VERSION ""

NS_ :

BS_:

BU_: XXX

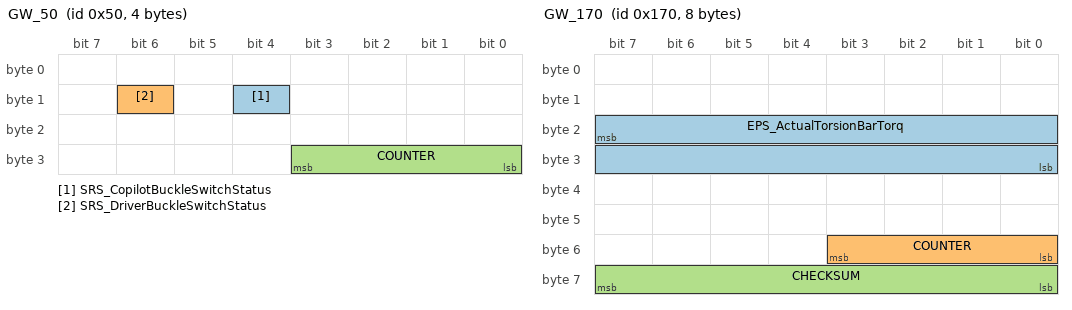
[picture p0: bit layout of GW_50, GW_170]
BO_ 80 GW_50: 4 XXX
 SG_ SRS_CopilotBuckleSwitchStatus : 12|1@0+ (1,0) [0|1] "" XXX
 SG_ SRS_DriverBuckleSwitchStatus : 14|1@0+ (1,0) [0|1] "" XXX
 SG_ COUNTER : 27|4@0+ (1,0) [0|15] "" XXX

BO_ 368 GW_170: 8 ESP
 SG_ EPS_ActualTorsionBarTorq : 23|16@0+ (1,-5533) [0|65535] "" XXX
 SG_ COUNTER : 51|4@0+ (1,0) [0|15] "" XXX
 SG_ CHECKSUM : 63|8@0+ (1,0) [0|255] "" XXX

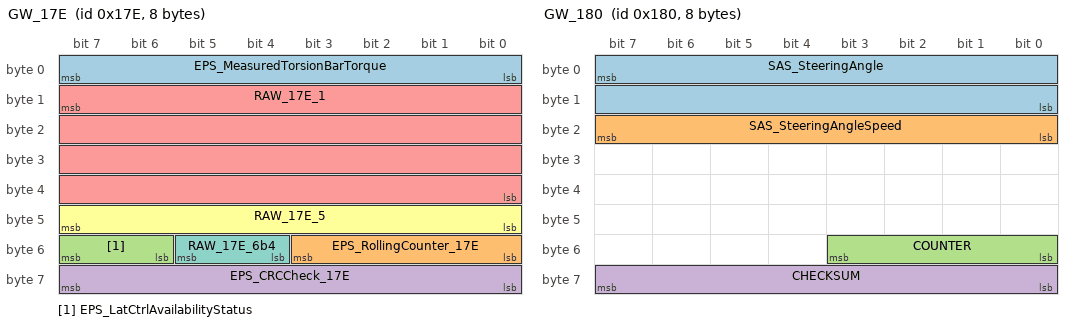
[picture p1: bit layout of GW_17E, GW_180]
BO_ 382 GW_17E: 8 XXX
 SG_ EPS_MeasuredTorsionBarTorque : 7|8@0+ (1,-126) [-126|129] "Nm" XXX
 SG_ EPS_RollingCounter_17E : 51|4@0+ (1,0) [0|15] "" XXX
 SG_ EPS_LatCtrlAvailabilityStatus : 55|2@0+ (1,0) [0|3] "" XXX
 SG_ EPS_CRCCheck_17E : 63|8@0+ (1,0) [0|255] "" XXX
 SG_ RAW_17E_1 : 15|32@0+ (1,0) [0|4294967295] "" XXX
 SG_ RAW_17E_5 : 47|8@0+ (1,0) [0|255] "" XXX
 SG_ RAW_17E_6b4 : 53|2@0+ (1,0) [0|3] "" XXX

BO_ 384 GW_180: 8 XXX
 SG_ SAS_SteeringAngle : 7|16@0- (0.015625,0) [-512|512] "deg" XXX
 SG_ SAS_SteeringAngleSpeed : 23|8@0+ (1,0) [0|255] "" XXX
 SG_ COUNTER : 51|4@0+ (1,0) [0|15] "" XXX
 SG_ CHECKSUM : 63|8@0+ (1,0) [0|255] "" XXX

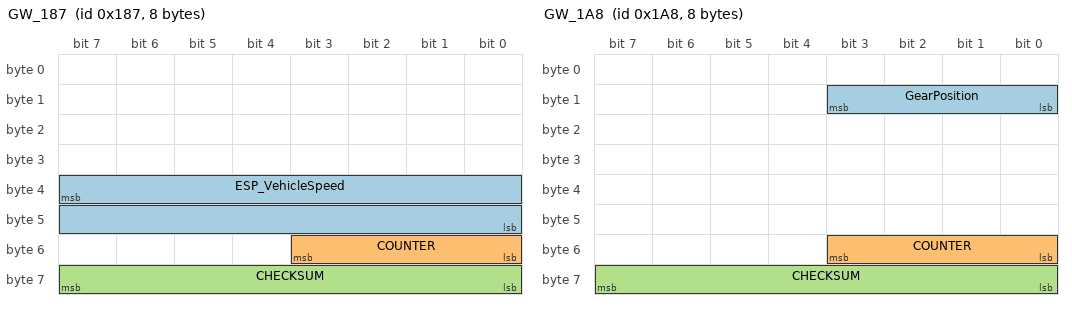
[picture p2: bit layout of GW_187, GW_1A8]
BO_ 391 GW_187: 8 XXX
 SG_ ESP_VehicleSpeed : 39|16@0+ (0.06,0) [0|255] "km/h" XXX
 SG_ COUNTER : 51|4@0+ (1,0) [0|15] "" XXX
 SG_ CHECKSUM : 63|8@0+ (1,0) [0|255] "" XXX

BO_ 392 GW_188: 8 XXX
 SG_ ESP_StatusByte : 7|8@0+ (1,0) [0|255] "" XXX

BO_ 407 GW_197: 8 XXX
 SG_ ESP_EspActive : 2|1@0+ (1,0) [0|1] "" XXX
 SG_ ESP_EspDisabled : 7|1@0+ (1,0) [0|1] "" XXX

BO_ 424 GW_1A8: 8 XXX
 SG_ GearPosition : 8|4@1+ (1,0) [0|15] "" XXX
 SG_ COUNTER : 51|4@0+ (1,0) [0|15] "" XXX
 SG_ CHECKSUM : 63|8@0+ (1,0) [0|255] "" XXX

BO_ 442 GW_1BA: 32 XXX
 SG_ ACC_MotorTorqueMinLimitRequest : 7|8@0+ (1,0) [0|255] "" XXX
 SG_ ACC_MotorTorqueMaxLimitRequest : 15|8@0+ (1,0) [0|255] "" XXX
 SG_ EPS_AngleCmd : 23|24@0- (0.0009765625,-6000.5) [-512|512] "deg" XXX
 SG_ ACC_RollingCounter_1BA : 51|4@0+ (1,0) [0|15] "" XXX
 SG_ ACC_CRCCheck_1BA : 63|8@0+ (1,0) [0|255] "" XXX

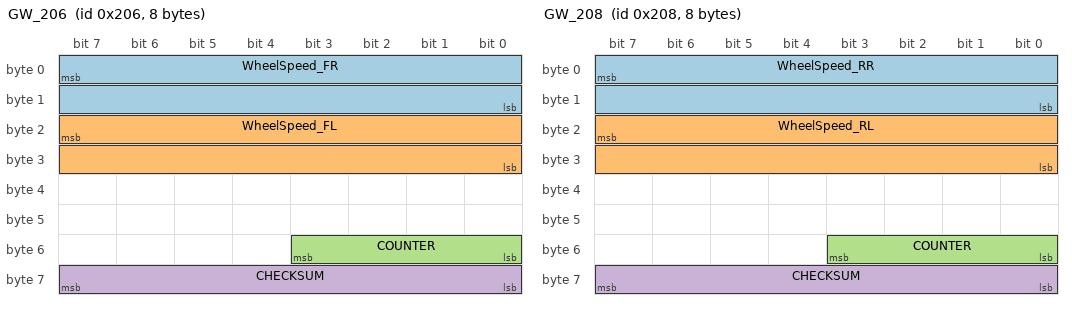
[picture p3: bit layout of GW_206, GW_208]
BO_ 518 GW_206: 8 XXX
 SG_ WheelSpeed_FR : 7|16@0+ (0.06,0) [0|255] "km/h" XXX
 SG_ WheelSpeed_FL : 23|16@0+ (0.06,0) [0|255] "km/h" XXX
 SG_ COUNTER : 51|4@0+ (1,0) [0|15] "" XXX
 SG_ CHECKSUM : 63|8@0+ (1,0) [0|255] "" XXX

BO_ 520 GW_208: 8 XXX
 SG_ WheelSpeed_RR : 7|16@0+ (0.06,0) [0|255] "km/h" XXX
 SG_ WheelSpeed_RL : 23|16@0+ (0.06,0) [0|255] "km/h" XXX
 SG_ COUNTER : 51|4@0+ (1,0) [0|15] "" XXX
 SG_ CHECKSUM : 63|8@0+ (1,0) [0|255] "" XXX

BO_ 580 GW_244: 32 XXX
 SG_ ACC_ACCTargetAcceleration : 7|16@0- (0.001,-25.6) [-10|10] "m/s2" XXX
 SG_ ACC_AEBCtrlType : 34|3@0+ (1,0) [0|7] "" XXX
 SG_ ACC_FCWPreWarning : 35|1@0+ (1,0) [0|1] "" XXX
 SG_ ACC_AccTrqReqActive : 44|1@0+ (1,0) [0|1] "" XXX
 SG_ ACC_RollingCounter_24E : 51|4@0+ (1,0) [0|15] "" XXX
 SG_ ACC_ACCMode : 54|3@0+ (1,0) [0|7] "" XXX
 SG_ ACC_ACCReq : 55|1@0+ (1,0) [0|1] "" XXX
 SG_ ACC_CRCCheck_24E : 63|8@0+ (1,0) [0|255] "" XXX
 SG_ ACC_AccTrqReq : 103|16@0+ (0.01,0) [0|45] "Nm" XXX
 SG_ ACC_RollingCounter_25E : 115|4@0+ (1,0) [0|15] "" XXX
 SG_ ACC_CRCCheck_25E : 127|8@0+ (1,0) [0|255] "" XXX
 SG_ RAW_244_2 : 23|16@0+ (1,0) [0|65535] "" XXX
 SG_ RAW_244_4b4 : 39|4@0+ (1,0) [0|15] "" XXX
 SG_ RAW_244_5b0 : 43|4@0+ (1,0) [0|15] "" XXX
 SG_ RAW_244_5b5 : 47|3@0+ (1,0) [0|7] "" XXX
 SG_ RAW_244_8 : 71|32@0+ (1,0) [0|4294967295] "" XXX
 SG_ RAW_244_14b4 : 119|4@0+ (1,0) [0|15] "" XXX
 SG_ RAW_244_16 : 135|32@0+ (1,0) [0|4294967295] "" XXX
 SG_ RAW_244_20 : 167|32@0+ (1,0) [0|4294967295] "" XXX
 SG_ RAW_244_24 : 199|32@0+ (1,0) [0|4294967295] "" XXX
 SG_ RAW_244_28 : 231|32@0+ (1,0) [0|4294967295] "" XXX

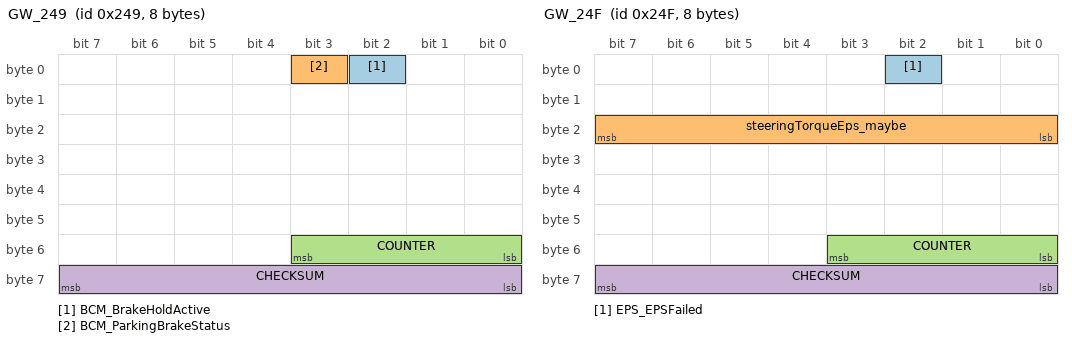
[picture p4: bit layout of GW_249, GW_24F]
BO_ 585 GW_249: 8 XXX
 SG_ BCM_BrakeHoldActive : 2|1@0+ (1,0) [0|1] "" XXX
 SG_ BCM_ParkingBrakeStatus : 3|1@0+ (1,0) [0|1] "" XXX
 SG_ COUNTER : 51|4@0+ (1,0) [0|15] "" XXX
 SG_ CHECKSUM : 63|8@0+ (1,0) [0|255] "" XXX

BO_ 591 GW_24F: 8 XXX
 SG_ EPS_EPSFailed : 2|1@0+ (1,0) [0|1] "" XXX
 SG_ steeringTorqueEps_maybe : 23|8@0- (0.1,0) [-12.8|12.7] "" XXX
 SG_ COUNTER : 51|4@0+ (1,0) [0|15] "" XXX
 SG_ CHECKSUM : 63|8@0+ (1,0) [0|255] "" XXX

BO_ 600 GW_258: 8 XXX
 SG_ GW258_Type M : 4|4@1+ (1,0) [0|15] "" XXX
 SG_ ESP_BrakePedalDepthHi m0 : 0|1@1+ (1,0) [0|1] "" XXX
 SG_ ESP_BrakePedalDepthLo m0 : 8|8@1+ (1,0) [0|255] "" XXX
 SG_ RAW_258_T1_1 m1 : 8|8@1+ (1,0) [0|255] "" XXX
 SG_ RAW_258_T1_2 m1 : 16|32@1+ (1,0) [0|4294967295] "" XXX
 SG_ RAW_258_T4_1 m4 : 8|8@1+ (1,0) [0|255] "" XXX
 SG_ RAW_258_T4_2 m4 : 16|32@1+ (1,0) [0|4294967295] "" XXX
 SG_ RAW_258_T5_1 m5 : 8|8@1+ (1,0) [0|255] "" XXX
 SG_ RAW_258_T5_2 m5 : 16|32@1+ (1,0) [0|4294967295] "" XXX
 SG_ COUNTER : 51|4@0+ (1,0) [0|15] "" XXX
 SG_ CHECKSUM : 63|8@0+ (1,0) [0|255] "" XXX

BO_ 618 GW_26A: 8 XXX
 SG_ EMS_AccelSwitch : 0|1@0+ (1,0) [0|1] "" XXX
 SG_ AcceleratorPedalPosition : 47|8@0+ (1,-31) [0|213] "%" XXX

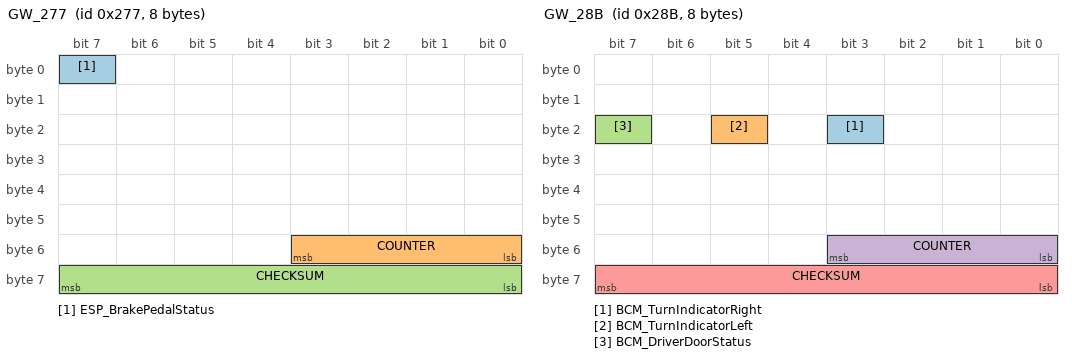
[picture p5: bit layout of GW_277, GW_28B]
BO_ 631 GW_277: 8 XXX
 SG_ ESP_BrakePedalStatus : 7|1@0+ (1,0) [0|1] "" XXX
 SG_ COUNTER : 51|4@0+ (1,0) [0|15] "" XXX
 SG_ CHECKSUM : 63|8@0+ (1,0) [0|255] "" XXX

BO_ 651 GW_28B: 8 XXX
 SG_ BCM_TurnIndicatorRight : 19|1@0+ (1,0) [0|1] "" XXX
 SG_ BCM_TurnIndicatorLeft : 21|1@0+ (1,0) [0|1] "" XXX
 SG_ BCM_DriverDoorStatus : 23|1@0+ (1,0) [0|1] "" XXX
 SG_ COUNTER : 51|4@0+ (1,0) [0|15] "" XXX
 SG_ CHECKSUM : 63|8@0+ (1,0) [0|255] "" XXX

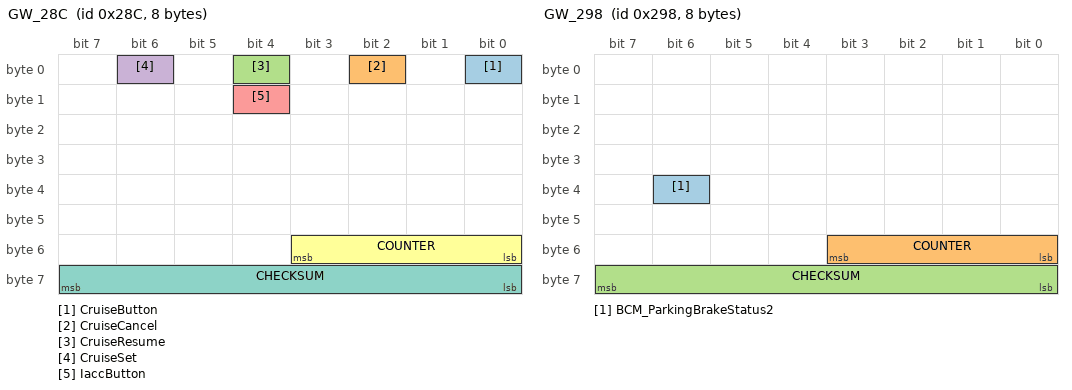
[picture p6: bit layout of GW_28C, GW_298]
BO_ 652 GW_28C: 8 XXX
 SG_ CruiseButton : 0|1@0+ (1,0) [0|1] "" XXX
 SG_ CruiseCancel : 2|1@0+ (1,0) [0|1] "" XXX
 SG_ CruiseResume : 4|1@0+ (1,0) [0|1] "" XXX
 SG_ CruiseSet : 6|1@0+ (1,0) [0|1] "" XXX
 SG_ IaccButton : 12|1@0+ (1,0) [0|1] "" XXX
 SG_ COUNTER : 51|4@0+ (1,0) [0|15] "" XXX
 SG_ CHECKSUM : 63|8@0+ (1,0) [0|255] "" XXX

BO_ 664 GW_298: 8 XXX
 SG_ BCM_ParkingBrakeStatus2 : 38|1@0+ (1,0) [0|1] "" XXX
 SG_ COUNTER : 51|4@0+ (1,0) [0|15] "" XXX
 SG_ CHECKSUM : 63|8@0+ (1,0) [0|255] "" XXX

BO_ 775 GW_307: 64 XXX
 SG_ ACC_SetSpeed : 7|16@0+ (0.0078125,0) [0|250] "km/h" XXX
 SG_ ACC_DistanceLevel : 17|2@0+ (1,0) [0|3] "" XXX
 SG_ ACC_RollingCounter_35E : 51|4@0+ (1,0) [0|15] "" XXX
 SG_ ACC_CRCCheck_35E : 63|8@0+ (1,0) [0|255] "" XXX
 SG_ ACC_RollingCounter_322 : 115|4@0+ (1,0) [0|15] "" XXX
 SG_ ACC_CRCCheck_322 : 127|8@0+ (1,0) [0|255] "" XXX
 SG_ ACC_RollingCounter_344 : 179|4@0+ (1,0) [0|15] "" XXX
 SG_ ACC_CRCCheck_344 : 191|8@0+ (1,0) [0|255] "" XXX
 SG_ ACC_RollingCounter_35F : 243|4@0+ (1,0) [0|15] "" XXX
 SG_ ACC_CRCCheck_35F : 255|8@0+ (1,0) [0|255] "" XXX
 SG_ RAW_307_2b2 : 23|6@0+ (1,0) [0|63] "" XXX
 SG_ RAW_307_3 : 31|24@0+ (1,0) [0|16777215] "" XXX
 SG_ RAW_307_6b4 : 55|4@0+ (1,0) [0|15] "" XXX
 SG_ RAW_307_8 : 71|32@0+ (1,0) [0|4294967295] "" XXX
 SG_ RAW_307_12 : 103|16@0+ (1,0) [0|65535] "" XXX
 SG_ RAW_307_14b4 : 119|4@0+ (1,0) [0|15] "" XXX
 SG_ RAW_307_16 : 135|32@0+ (1,0) [0|4294967295] "" XXX
 SG_ RAW_307_20 : 167|16@0+ (1,0) [0|65535] "" XXX
 SG_ RAW_307_22b4 : 183|4@0+ (1,0) [0|15] "" XXX
 SG_ RAW_307_24 : 199|32@0+ (1,0) [0|4294967295] "" XXX
 SG_ RAW_307_28 : 231|16@0+ (1,0) [0|65535] "" XXX
 SG_ RAW_307_30b4 : 247|4@0+ (1,0) [0|15] "" XXX
 SG_ RAW_307_32 : 263|32@0+ (1,0) [0|4294967295] "" XXX
 SG_ RAW_307_36 : 295|32@0+ (1,0) [0|4294967295] "" XXX
 SG_ RAW_307_40 : 327|32@0+ (1,0) [0|4294967295] "" XXX
 SG_ RAW_307_44 : 359|32@0+ (1,0) [0|4294967295] "" XXX
 SG_ RAW_307_48 : 391|32@0+ (1,0) [0|4294967295] "" XXX
 SG_ RAW_307_52 : 423|32@0+ (1,0) [0|4294967295] "" XXX
 SG_ RAW_307_56 : 455|32@0+ (1,0) [0|4294967295] "" XXX
 SG_ RAW_307_60 : 487|32@0+ (1,0) [0|4294967295] "" XXX

BO_ 794 GW_31A: 64 XXX
 SG_ GW31A_BSD_WarnLeft : 43|1@0+ (1,0) [0|1] "" XXX
 SG_ GW31A_BSD_WarnRight : 44|1@0+ (1,0) [0|1] "" XXX
 SG_ GW31A_BSD_WarnActive : 46|1@0+ (1,0) [0|1] "" XXX
 SG_ ACC_RollingCounter_36D : 51|4@0+ (1,0) [0|15] "" XXX
 SG_ ACC_CRCCheck_36D : 63|8@0+ (1,0) [0|255] "" XXX
 SG_ ACC_IACCHWAEnable : 68|1@0+ (1,0) [0|1] "" XXX
 SG_ ACC_TargetBasedLateralControl : 96|1@0+ (1,0) [0|1] "" XXX
 SG_ ACC_RollingCounter_30A : 115|4@0+ (1,0) [0|15] "" XXX
 SG_ ACC_CRCCheck_30A : 127|8@0+ (1,0) [0|255] "" XXX
 SG_ ACC_IACCHWAMode : 135|3@0+ (1,0) [0|7] "" XXX
 SG_ ACC_RollingCounter_30D : 179|4@0+ (1,0) [0|15] "" XXX
 SG_ ACC_CRCCheck_30D : 191|8@0+ (1,0) [0|255] "" XXX
 SG_ ACC_RollingCounter_367 : 243|4@0+ (1,0) [0|15] "" XXX
 SG_ ACC_CRCCheck_367 : 255|8@0+ (1,0) [0|255] "" XXX
 SG_ RAW_31A_0 : 7|32@0+ (1,0) [0|4294967295] "" XXX
 SG_ RAW_31A_4 : 39|8@0+ (1,0) [0|255] "" XXX
 SG_ RAW_31A_5b0 : 42|3@0+ (1,0) [0|7] "" XXX
 SG_ RAW_31A_5b5 : 45|1@0+ (1,0) [0|1] "" XXX
 SG_ RAW_31A_5b7 : 47|1@0+ (1,0) [0|1] "" XXX
 SG_ RAW_31A_6b4 : 55|4@0+ (1,0) [0|15] "" XXX
 SG_ RAW_31A_8b0 : 67|4@0+ (1,0) [0|15] "" XXX
 SG_ RAW_31A_8b5 : 71|3@0+ (1,0) [0|7] "" XXX
 SG_ RAW_31A_9 : 79|24@0+ (1,0) [0|16777215] "" XXX
 SG_ RAW_31A_12b1 : 103|7@0+ (1,0) [0|127] "" XXX
 SG_ RAW_31A_13 : 111|8@0+ (1,0) [0|255] "" XXX
 SG_ RAW_31A_14b4 : 119|4@0+ (1,0) [0|15] "" XXX
 SG_ RAW_31A_16b0 : 132|5@0+ (1,0) [0|31] "" XXX
 SG_ RAW_31A_17 : 143|32@0+ (1,0) [0|4294967295] "" XXX
 SG_ RAW_31A_21 : 175|8@0+ (1,0) [0|255] "" XXX
 SG_ RAW_31A_22b4 : 183|4@0+ (1,0) [0|15] "" XXX
 SG_ RAW_31A_24 : 199|32@0+ (1,0) [0|4294967295] "" XXX
 SG_ RAW_31A_28 : 231|16@0+ (1,0) [0|65535] "" XXX
 SG_ RAW_31A_30b4 : 247|4@0+ (1,0) [0|15] "" XXX
 SG_ RAW_31A_32 : 263|32@0+ (1,0) [0|4294967295] "" XXX
 SG_ RAW_31A_36 : 295|32@0+ (1,0) [0|4294967295] "" XXX
 SG_ RAW_31A_40 : 327|32@0+ (1,0) [0|4294967295] "" XXX
 SG_ RAW_31A_44 : 359|32@0+ (1,0) [0|4294967295] "" XXX
 SG_ RAW_31A_48 : 391|32@0+ (1,0) [0|4294967295] "" XXX
 SG_ RAW_31A_52 : 423|32@0+ (1,0) [0|4294967295] "" XXX
 SG_ RAW_31A_56 : 455|32@0+ (1,0) [0|4294967295] "" XXX
 SG_ RAW_31A_60 : 487|32@0+ (1,0) [0|4294967295] "" XXX

CM_ BO_ 368 "EPS shiji niuju (EPS actual torsion bar torque GW_170, byte2-3, dai yanzheng)";
CM_ SG_ 368 EPS_ActualTorsionBarTorq "EPS shiji niuju (actual torsion bar torque, 23|16@0+ (1,-5533), dai yanzheng: 01.csv zhong byte2-3 bu lianxu, byte3 zhiyou 22 distinct zhi, kending yichang)";
CM_ BO_ 382 "EPS celiang niuju (EPS measured torsion bar torque GW_17E, byte0)";
CM_ SG_ 382 EPS_MeasuredTorsionBarTorque "jiashiyuan niuju (driver torque Nm, byte0 wufuhao + offset -126, 01.csv yanzheng: zhixing fenbu 0x7E=126 fengzhi, fanwei 81~220 -> -45~+94 Nm, jiu dingyi 7|12@0- cuowu)";
CM_ SG_ 382 EPS_LatCtrlAvailabilityStatus "CESHI hengxiang kongzhi keji zhuangtai (EPS lat ctrl availability, byte6 bits7,6, 01.csv zhiqu {0,1}, 0=83% 1=17%)";
CM_ BO_ 384 "zhuanxiangjiao (steering angle, 0|16@0- yanzheng)";
CM_ SG_ 384 SAS_SteeringAngle "zhuanxiangjiao du (steering angle deg)";
CM_ SG_ 384 SAS_SteeringAngleSpeed "zhuanxiangjiao sudu (steering angle rate)";
CM_ BO_ 391 "chesu xinhao (vehicle speed, GW_187)";
CM_ SG_ 391 ESP_VehicleSpeed "chesu km/h (vehicle speed)";
CM_ BO_ 392 "ESP xinxi (ESP info GW_188, byte0 zhuangtai, dai shiche yanzheng)";
CM_ SG_ 392 ESP_StatusByte "ESP zhuangtai zhi (ESP status raw byte0, dai yanzheng: 01.csv zhi {0x00,0x01,0x20,0x60}, yubei espActive/espDisabled rongyu)";
CM_ BO_ 407 "ESP zhuangtai (ESP state GW_197, zhong zhiyindu, dai shiche yanzheng)";
CM_ SG_ 407 ESP_EspActive "ESP ganyu (ESP active intervention, byte0 bit2, 0x01->0x05 fanzhuan)";
CM_ SG_ 407 ESP_EspDisabled "ESP guanbi (ESP disabled, byte0 bit7, 01.csv qidong t=0s shi byte0=0xC0, zhihou zhuan 0x01)";
CM_ BO_ 424 "dangwei (gear, 0x1A8 byte1 low nibble: 0x00=N, 0x01-0x07=1-7, 0x09=R, 0x0A=P)";
CM_ SG_ 424 GearPosition "dangwei";
CM_ BO_ 442 "ADAS kongzhi mingling (ACC control command GW_1BA, 32 bytes)";
CM_ SG_ 442 EPS_AngleCmd "jiaodu mingling (EPS angle command: raw24 = 0x5DC200 + deg*1024, i.e. 1/1024 deg/LSB with offset -6000.5; equals GW_180 SAS_SteeringAngle_raw * 16)";
CM_ SG_ 518 WheelSpeed_FR "Special raw value 0x4000 = standstill (while 0x187 speed=0x0000); do not decode as vehicle speed.";
CM_ SG_ 518 WheelSpeed_FL "Special raw value 0x4000 = standstill (while 0x187 speed=0x0000); do not decode as vehicle speed.";
CM_ SG_ 520 WheelSpeed_RR "Special raw value 0x4000 = standstill (while 0x187 speed=0x0000); do not decode as vehicle speed.";
CM_ SG_ 520 WheelSpeed_RL "Special raw value 0x4000 = standstill (while 0x187 speed=0x0000); do not decode as vehicle speed.";
CM_ BO_ 580 "ACC zhuangtai (ACC status GW_244, 32 bytes)";
CM_ SG_ 580 ACC_ACCTargetAcceleration "ACC mubiao jiasudu (ACC target acceleration m/s2, raw*0.001-25.6)";
CM_ SG_ 580 ACC_AEBCtrlType "AEB kongzhi leixing (AEB control type, 0=none)";
CM_ SG_ 580 ACC_FCWPreWarning "QZDY yujing (FCW pre-warning, 0=no 1=yes)";
CM_ SG_ 580 ACC_ACCMode "ACC moshi (ACC mode 54|3@0+, 2=standby 3=active 7=fault)";
CM_ SG_ 580 ACC_ACCReq "ACC qingqiu (ACC request, byte6 bit7)";
CM_ SG_ 580 ACC_AccTrqReq "ACC niuju qingqiu (ACC torque request, non-zero=active; 01.csv xiuzheng: raw wei 4 de beishu, fanwei 108~4308, scale=0.01 -> [1.08,43.08] Nm)";
CM_ BO_ 585 "BCM zhuangtai (BCM state GW_249, zhong zhiyindu, dai shiche yanzheng)";
CM_ SG_ 585 BCM_BrakeHoldActive "zidong zhuche (auto hold, byte0 bit2, oufa 0x04)";
CM_ SG_ 585 BCM_ParkingBrakeStatus "zhuchedong (parking brake, byte0 bit3, 01.csv t=199s hou wei 0x08)";
CM_ BO_ 591 "EPS guzhuang (EPS fault GW_24F, 8 bytes)";
CM_ SG_ 591 EPS_EPSFailed "EPS guzhuang (EPS failed, byte0 bit2, WUDINGYI: byte0 shi fuzhi xinhao jingzhi=1 kuaizhuan=43, zhengchang kuaiman zhuanxiang shi wuchufa 2%)";
CM_ SG_ 591 steeringTorqueEps_maybe "EPS niuju yubei (EPS torque maybe, byte2 youfuhao 0.1, 01.csv 127 wei zhongxin, yu 0x17E byte0 danziangliang)";
CM_ BO_ 600 "shache taban shendu (brake pedal depth GW_258, muxed subframes; 01.csv quancheng Type={0,1,4,5}, Type0=12373zhen shendu[0,485] 500=100%, Type1/4/5 wei qita zizhen; COUNTER/CHECKSUM za sanyouzhen jun cunzai, gonggong)";
CM_ SG_ 600 GW258_Type "zizhen leixing (subframe type, byte0 high nibble: 0=PedalFrame, 1/4/5=other subframes, 01.csv Type 0/1/4/5)";
CM_ SG_ 600 ESP_BrakePedalDepthHi "shache taban shendu di 9 wei (brake pedal depth bit8, value=Lo|Hi<<8, 500=100%)";
CM_ SG_ 600 ESP_BrakePedalDepthLo "shache taban shendu di 8 wei (brake pedal depth low byte)";
CM_ BO_ 618 "youmen taban (accel pedal GW_26A)";
CM_ SG_ 618 EMS_AccelSwitch "youmen kaiguan byte0 bit0 (accel switch, 0=release 1=pressed)";
CM_ SG_ 618 AcceleratorPedalPosition "youmen kaidu % (accel pedal position, byte5 raw: 31=0%, 136=floor by accanjian.csv)";
CM_ BO_ 631 "shache taban (brake pedal GW_277)";
CM_ BO_ 651 "cheshen kongzhi BCM (body control: doors/turn signals)";
CM_ SG_ 651 BCM_TurnIndicatorRight "you zhuanxiang deng (right turn signal)";
CM_ SG_ 651 BCM_TurnIndicatorLeft "zuo zhuanxiang deng (left turn signal)";
CM_ BO_ 652 "fangxiangpan anjian (steering wheel buttons)";
CM_ SG_ 652 CruiseButton "dingsu";
CM_ SG_ 652 CruiseCancel "Exit_IACC";
CM_ SG_ 652 CruiseResume "RES+ anjian";
CM_ SG_ 652 CruiseSet "SET- anjian";
CM_ SG_ 652 IaccButton "IACC anjian";
CM_ BO_ 664 "BCM zhuangtai 2 (BCM state GW_298, rongyu, dai shiche yanzheng)";
CM_ SG_ 664 BCM_ParkingBrakeStatus2 "zhuchedong rongyu (parking brake redundant, byte4 bit6, 0x08->0x48 fanzhuan)";
CM_ BO_ 775 "ACC shezhi (ACC set speed/distance GW_307, 64 bytes, 4x16-byte sub-frames)";
CM_ SG_ 775 ACC_SetSpeed "ACC shezhi chesu (ACC set speed km/h, raw*0.0078125, verified 80.25/85.25/69.25)";
CM_ SG_ 775 ACC_DistanceLevel "ACC cheju dengji (ACC distance level, 0-3)";
CM_ BO_ 794 "IACC zhuangtai (IACC HWA status GW_31A, 64 bytes, 4x16-byte sub-frames)";
CM_ SG_ 794 GW31A_BSD_WarnLeft "chefanglaiche";
CM_ SG_ 794 GW31A_BSD_WarnRight "chefanglaiche";
CM_ SG_ 794 GW31A_BSD_WarnActive "chefanglaiche";
CM_ SG_ 794 ACC_IACCHWAEnable "IACC HWA keji (IACC HWA available, byte8 bit4, verified byte8=0x71->1)";
CM_ SG_ 794 ACC_TargetBasedLateralControl "HCEngji mubiao hengxiang kongzhi (HWA target-based lateral control, byte12 bit0)";
CM_ SG_ 794 ACC_IACCHWAMode "IACC HWA moshi (IACC HWA mode 135|3@0+, 7=fault)";
VAL_ 80 SRS_CopilotBuckleSwitchStatus 0 "close" 1 "open";
VAL_ 80 SRS_DriverBuckleSwitchStatus 0 "close" 1 "open";
VAL_ 382 EPS_LatCtrlAvailabilityStatus 0 "available" 1 "unavailable";
VAL_ 407 ESP_EspActive 0 "inactive" 1 "active";
VAL_ 407 ESP_EspDisabled 0 "enabled" 1 "disabled";
VAL_ 424 GearPosition 0 "N" 1 "D1" 2 "2" 3 "3" 4 "4" 5 "5" 6 "6" 7 "7" 9 "R" 10 "P";
VAL_ 580 ACC_AEBCtrlType 0 "none" 1 "active";
VAL_ 580 ACC_FCWPreWarning 0 "no" 1 "yes";
VAL_ 580 ACC_AccTrqReqActive 0 "no" 1 "yes";
VAL_ 580 ACC_ACCMode 0 "off" 1 "inactive" 2 "standby" 3 "active" 7 "fault";
VAL_ 580 ACC_ACCReq 0 "no" 1 "yes";
VAL_ 585 BCM_BrakeHoldActive 0 "inactive" 1 "active";
VAL_ 585 BCM_ParkingBrakeStatus 0 "release" 1 "applied";
VAL_ 591 EPS_EPSFailed 0 "no" 1 "yes";
VAL_ 600 GW258_Type 0 "PedalFrame" 1 "Subframe1" 4 "Subframe4" 5 "Subframe5";
VAL_ 618 EMS_AccelSwitch 0 "release" 1 "pressed";
VAL_ 631 ESP_BrakePedalStatus 0 "release" 1 "pressed";
VAL_ 651 BCM_TurnIndicatorRight 0 "no" 1 "turn_right";
VAL_ 651 BCM_TurnIndicatorLeft 0 "no" 1 "turn_left";
VAL_ 651 BCM_DriverDoorStatus 0 "close" 1 "open";
VAL_ 652 CruiseButton 0 "no" 1 "Press";
VAL_ 652 CruiseCancel 0 "no" 1 "Press";
VAL_ 652 CruiseResume 0 "no" 1 "reset/+";
VAL_ 652 CruiseSet 0 "no" 1 "set-";
VAL_ 652 IaccButton 0 "no" 1 "On_IACC";
VAL_ 664 BCM_ParkingBrakeStatus2 0 "release" 1 "applied";
VAL_ 794 ACC_IACCHWAEnable 0 "no" 1 "yes";
VAL_ 794 ACC_TargetBasedLateralControl 0 "no" 1 "yes";
VAL_ 794 ACC_IACCHWAMode 0 "off" 7 "fault";
